# PIC16LF1455 register map
Vendor: Microchip
Architecture 16Exxx. Special function registers and configuration words.
Registers are 8-bit, read-write, no defined reset value unless marked. A register's access mark holds for its fields unless they carry their own. Addresses are absolute, and some are shared; only a register's first bit layout is shown; lines under a group give offsets from that group; [hi:lo] are bit positions; {n}, {i} and the like mark numbered series; 'fields as' and 'values as' point back to an identical list; <NAME> marks a mode.

## Further device data
pins=1: VDD; 2: RA5/SOSCI/T1CKI/PWM2/CLKIN/OSC1; 3: RA4/AN3/SDO/T1G/CLKR/SOSCO/CLKOUT/OSC2; 4: RA3/SS/T1G/MCLR/VPP; 5: RC5/RX_DT/T0CKI/PWM1/CWG1A; 6: RC4/TX_CK/C2OUT/C1OUT/CWG1B; 7: RC3/AN7/SS/PWM2/CLKR/C2IN3-/C1IN3-/DACOUT2; 8: RC2/AN6/SDO/C2IN2-/C1IN2-/DACOUT1; 9: RC1/AN5/INT/SDI/SDA/CWGFLT/C2IN1-/C1IN1-/ICSPCLK; 10: RC0/AN4/SCK/SCL/C2IN+/C1IN+/VREF+/ICSPDAT; 11: VUSB3V3; 12: RA1/D-/ICSPCLK; 13: RA0/D+/ICSPDAT; 14: VSS

## A4_cwg
0x691 CWG1DBR — (power-on value --xxxxxx)
  [5:0] CWG1DBR
0x692 CWG1DBF — (power-on value --xxxxxx)
  [5:0] CWG1DBF
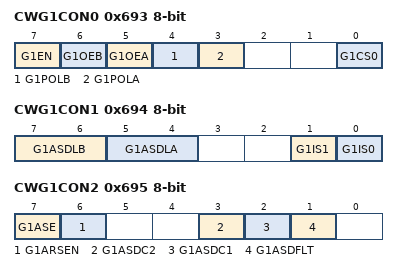
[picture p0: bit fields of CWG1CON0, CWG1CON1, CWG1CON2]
0x693 CWG1CON0 — Configurable logic cell control (power-on value 00000--x)
  [7] G1EN, [6] G1OEB, [5] G1OEA, [4] G1POLB, [3] G1POLA, [0] G1CS0
0x694 CWG1CON1 — (power-on value xxxx--xx)
  [7:6] G1ASDLB, [5:4] G1ASDLA, [1] G1IS1, [0] G1IS0
0x695 CWG1CON2 — (power-on value xx--xxx-)
  [7] G1ASE, [6] G1ARSEN, [3] G1ASDC2, [2] G1ASDC1, [1] G1ASDFLT

## usb_fscore
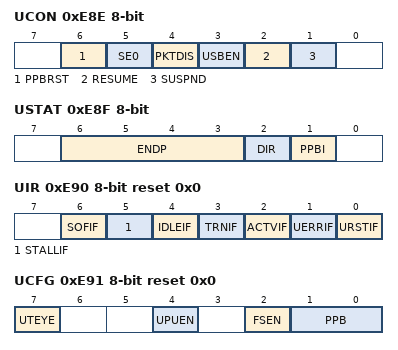
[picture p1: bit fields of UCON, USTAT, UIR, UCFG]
0xE8E UCON — (power-on value -0x0000-)
  [6] PPBRST, [5] SE0 ro, [4] PKTDIS, [3] USBEN, [2] RESUME, [1] SUSPND
0xE8F USTAT ro — (power-on value -xxxxxx-)
  [6:3] ENDP, [2] DIR, [1] PPBI
0xE90 UIR reset 0x0
  [6] SOFIF, [5] STALLIF, [4] IDLEIF, [3] TRNIF, [2] ACTVIF, [1] UERRIF ro, [0] URSTIF
0xE91 UCFG reset 0x0
  [7] UTEYE, [4] UPUEN, [2] FSEN, [1:0] PPB
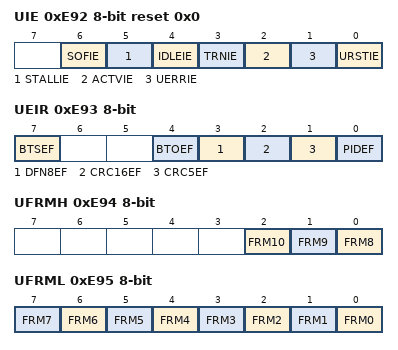
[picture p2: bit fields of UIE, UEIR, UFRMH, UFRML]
0xE92 UIE reset 0x0
  [6] SOFIE, [5] STALLIE, [4] IDLEIE, [3] TRNIE, [2] ACTVIE, [1] UERRIE, [0] URSTIE
0xE93 UEIR ro — (power-on value x--xxxxx)
  [7] BTSEF, [4] BTOEF, [3] DFN8EF, [2] CRC16EF, [1] CRC5EF, [0] PIDEF
0xE94 UFRMH — (power-on value -----xxx)
  [2] FRM10, [1] FRM9, [0] FRM8
0xE95 UFRML — (power-on value xxxxxxxx)
  [n] FRM{n} (n=0..7)
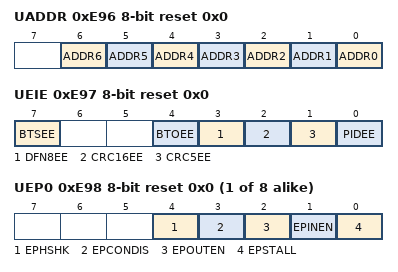
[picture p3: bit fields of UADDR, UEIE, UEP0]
0xE96 UADDR reset 0x0
  [n] ADDR{n} (n=0..6)
0xE97 UEIE reset 0x0
  [7] BTSEE, [4] BTOEE, [3] DFN8EE, [2] CRC16EE, [1] CRC5EE, [0] PIDEE
{0xE98+i} UEP{i} reset 0x0 (i=0..7)
  [4] EPHSHK, [3] EPCONDIS, [2] EPOUTEN, [1] EPINEN, [0] EPSTALL
